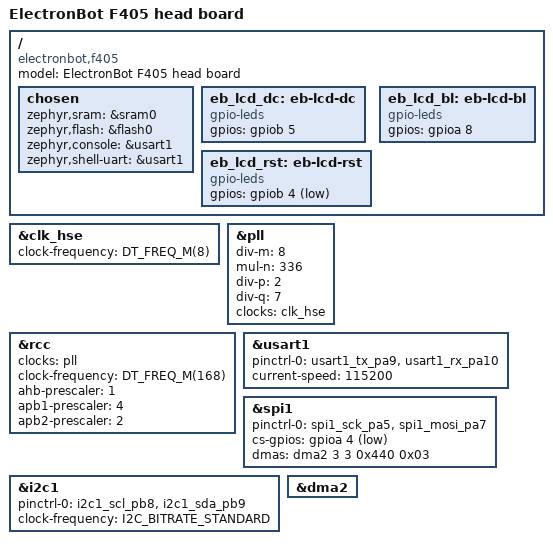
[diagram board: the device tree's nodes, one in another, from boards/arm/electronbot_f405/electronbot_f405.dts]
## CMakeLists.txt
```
# SPDX-License-Identifier: Apache-2.0
cmake_minimum_required(VERSION 3.20.0)

find_package(Zephyr REQUIRED HINTS $ENV{ZEPHYR_BASE})
project(electronbot_zephyr C)

target_sources(app PRIVATE
  src/main.c
  src/robot.c
  src/protocol.c
  src/usb_app.c
  src/display.c
  src/servo_bus.c
)
```

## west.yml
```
# West manifest for the ElectronBot Zephyr head firmware.
#
# Usage (creates a workspace that pulls Zephyr + HAL modules next to this app):
#   west init -l v2/firmware/electronbot-zephyr
#   west update
#   west build -b electronbot_f405 v2/firmware/electronbot-zephyr
#
# Pin to a known-good Zephyr release; bump deliberately.
manifest:
  remotes:
    - name: zephyrproject-rtos
      url-base: https://github.com/zephyrproject-rtos

  projects:
    - name: zephyr
      remote: zephyrproject-rtos
      revision: v3.7.0
      import:
        # Only pull the modules this app needs (HALs/CMSIS) to keep it lean.
        name-allowlist:
          - cmsis
          - hal_stm32

  self:
    path: application
```

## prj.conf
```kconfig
# ElectronBot head firmware (Zephyr) - application config.

# Core
CONFIG_LOG=y
CONFIG_GPIO=y
CONFIG_SPI=y
CONFIG_I2C=y
CONFIG_DMA=y

# FPU (Cortex-M4F)
CONFIG_FPU=y

# USB device stack (legacy stack shown; for usb_device_next swap the symbols).
CONFIG_USB_DEVICE_STACK=y
CONFIG_USB_DEVICE_VID=0x1001
CONFIG_USB_DEVICE_PID=0x8023
CONFIG_USB_DEVICE_MANUFACTURER="Pengzhihui"
CONFIG_USB_DEVICE_PRODUCT="ElectronBot@PZH"

# Reasonable heap/stack for the 43232-byte ping-pong buffers (in BSS, not heap).
CONFIG_MAIN_STACK_SIZE=4096
CONFIG_HEAP_MEM_POOL_SIZE=8192

# Helpful while bringing up.
CONFIG_LOG_DEFAULT_LEVEL=3
CONFIG_ASSERT=y
```

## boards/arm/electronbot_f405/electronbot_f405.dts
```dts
/*
 * ElectronBot head board - STM32F405RGT6.
 *
 * Pin assignments below follow the original design (SPI1 for the GC9A01 LCD,
 * I2C1 SCL=PB8 / SDA=PB9 for the servo bus). CONFIRM against 1.Hardware before
 * relying on them - marked with TODO where the schematic is the source of truth.
 */
/dts-v1/;
#include <st/f4/stm32f405Xg.dtsi>
#include <st/f4/stm32f405rgtx-pinctrl.dtsi>
#include <zephyr/dt-bindings/gpio/gpio.h>

/ {
	model = "ElectronBot F405 head board";
	compatible = "electronbot,f405";

	chosen {
		zephyr,sram = &sram0;
		zephyr,flash = &flash0;
		zephyr,console = &usart1;
		zephyr,shell-uart = &usart1;
	};

	/* LCD control GPIOs (DC / RST / backlight). TODO: confirm pins. */
	eb_lcd_dc: eb-lcd-dc {
		compatible = "gpio-leds";
		gpios = <&gpiob 5 GPIO_ACTIVE_HIGH>;
	};
	eb_lcd_rst: eb-lcd-rst {
		compatible = "gpio-leds";
		gpios = <&gpiob 4 GPIO_ACTIVE_LOW>;
	};
	eb_lcd_bl: eb-lcd-bl {
		compatible = "gpio-leds";
		gpios = <&gpioa 8 GPIO_ACTIVE_HIGH>;
	};
};

/* High-speed external crystal (8 MHz on the original board). */
&clk_hse {
	clock-frequency = <DT_FREQ_M(8)>;
	status = "okay";
};

&pll {
	div-m = <8>;
	mul-n = <336>;
	div-p = <2>;
	div-q = <7>;
	clocks = <&clk_hse>;
	status = "okay";
};

&rcc {
	clocks = <&pll>;
	clock-frequency = <DT_FREQ_M(168)>;
	ahb-prescaler = <1>;
	apb1-prescaler = <4>;
	apb2-prescaler = <2>;
};

&usart1 {
	pinctrl-0 = <&usart1_tx_pa9 &usart1_rx_pa10>;
	pinctrl-names = "default";
	current-speed = <115200>;
	status = "okay";
};

/* GC9A01 LCD bus. */
eb_lcd_spi: &spi1 {
	pinctrl-0 = <&spi1_sck_pa5 &spi1_mosi_pa7>;
	pinctrl-names = "default";
	cs-gpios = <&gpioa 4 GPIO_ACTIVE_LOW>;   /* TODO: confirm CS pin */
	status = "okay";
	/* DMA wiring for stripe streaming. TODO: confirm DMA stream/channel. */
	dmas = <&dma2 3 3 0x440 0x03>;
	dma-names = "tx";
};

/* Servo bus (I2C master). SCL=PB8, SDA=PB9 per the original firmware. */
eb_servo_i2c: &i2c1 {
	pinctrl-0 = <&i2c1_scl_pb8 &i2c1_sda_pb9>;
	pinctrl-names = "default";
	clock-frequency = <I2C_BITRATE_STANDARD>;
	status = "okay";
};

&dma2 {
	status = "okay";
};
```

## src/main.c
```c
/*
 * ElectronBot head firmware - Zephyr port entry point.
 *
 * Target: STM32F405RGT6 (Cortex-M4F). Replaces the original CubeMX/HAL +
 * FreeRTOS super-loop firmware while keeping the host SDK protocol unchanged.
 */
#include <zephyr/kernel.h>
#include <zephyr/logging/log.h>

#include "robot.h"

LOG_MODULE_REGISTER(eb_main, LOG_LEVEL_INF);

int main(void)
{
	LOG_INF("ElectronBot-zephyr boot");

	int rc = eb_robot_init();

	if (rc) {
		LOG_ERR("init failed: %d", rc);
		return rc;
	}

	eb_robot_run(); /* never returns */
	return 0;
}
```

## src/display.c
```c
/*
 * GC9A01 stripe streaming driver (Zephyr SPI + GPIO).
 *
 * Implementation notes:
 *  - Uses the Zephyr SPI driver (async API for DMA-backed transfers where the
 *    SoC SPI supports it). On STM32 the SPI DMA is wired via the devicetree.
 *  - DC/CS/RST/backlight are GPIOs from the devicetree (see board overlay).
 *  - The init sequence below mirrors the original firmware's GC9A01 magic
 *    registers (0xEF / 0xEB / 0xFE ... MADCTL 0x36, COLMOD 0x3A, etc.).
 *
 * Hardware-tuning TODOs are marked; these need a scope/panel to finalize.
 */
#include <zephyr/kernel.h>
#include <zephyr/device.h>
#include <zephyr/drivers/spi.h>
#include <zephyr/drivers/gpio.h>
#include <zephyr/logging/log.h>

#include "display.h"
#include "protocol.h"

LOG_MODULE_REGISTER(eb_display, LOG_LEVEL_INF);

#define SPI_NODE   DT_NODELABEL(eb_lcd_spi)
#define DC_NODE    DT_NODELABEL(eb_lcd_dc)
#define RST_NODE   DT_NODELABEL(eb_lcd_rst)
#define BL_NODE    DT_NODELABEL(eb_lcd_bl)

static const struct device *spi_dev;
static struct gpio_dt_spec dc_gpio  = GPIO_DT_SPEC_GET_OR(DC_NODE,  gpios, {0});
static struct gpio_dt_spec rst_gpio = GPIO_DT_SPEC_GET_OR(RST_NODE, gpios, {0});
static struct gpio_dt_spec bl_gpio  = GPIO_DT_SPEC_GET_OR(BL_NODE,  gpios, {0});

static struct spi_config spi_cfg = {
	.frequency = 40000000U, /* TODO: confirm max stable SPI clock for the panel */
	.operation = SPI_WORD_SET(8) | SPI_TRANSFER_MSB | SPI_OP_MODE_MASTER,
	.slave = 0,
};

/* GC9A01 init program: {cmd, n_args, args...}. Condensed from the original
 * firmware's screen.cpp magic sequence. */
static const uint8_t gc9a01_init[] = {
	0xEF, 0,
	0xEB, 1, 0x14,
	0xFE, 0,
	0xEF, 0,
	0xEB, 1, 0x14,
	0x84, 1, 0x40,
	0x86, 1, 0xFF,
	0x88, 1, 0x0A,
	0x8A, 1, 0x00,
	0x8D, 1, 0x14,
	0x36, 1, 0x48,        /* MADCTL */
	0x3A, 1, 0x06,        /* COLMOD: 18-bit (3 bytes/pixel) */
	0x90, 4, 0x08, 0x08, 0x08, 0x08,
	0xBD, 1, 0x06,
	0xBC, 1, 0x00,
	0xFF, 3, 0x60, 0x01, 0x04,
	0xC3, 1, 0x13,
	0xC4, 1, 0x13,
	0xC9, 1, 0x22,
	0xBE, 1, 0x11,
	0xE1, 2, 0x10, 0x0E,
	0xDF, 3, 0x21, 0x0c, 0x02,
	0x11, 0,              /* sleep out */
	0x00                  /* terminator (cmd 0x00 unused -> end) */
};

static int spi_write_bytes(const uint8_t *data, size_t len)
{
	struct spi_buf buf = { .buf = (void *)data, .len = len };
	struct spi_buf_set set = { .buffers = &buf, .count = 1 };

	return spi_write(spi_dev, &spi_cfg, &set);
}

static void write_cmd(uint8_t cmd)
{
	gpio_pin_set_dt(&dc_gpio, 0); /* command */
	spi_write_bytes(&cmd, 1);
}

static void write_data(const uint8_t *data, size_t len)
{
	gpio_pin_set_dt(&dc_gpio, 1); /* data */
	spi_write_bytes(data, len);
}

static void run_init_program(const uint8_t *prog)
{
	size_t i = 0;

	while (prog[i] != 0x00 || i == 0) {
		uint8_t cmd = prog[i++];
		uint8_t n = prog[i++];

		write_cmd(cmd);
		if (n) {
			write_data(&prog[i], n);
			i += n;
		}
		if (cmd == 0x11) {
			k_msleep(120); /* sleep-out settle */
		}
		if (prog[i] == 0x00) {
			break;
		}
	}
}

int eb_display_init(void)
{
	spi_dev = DEVICE_DT_GET(SPI_NODE);
	if (!device_is_ready(spi_dev)) {
		LOG_ERR("SPI not ready");
		return -ENODEV;
	}
	gpio_pin_configure_dt(&dc_gpio, GPIO_OUTPUT_INACTIVE);
	gpio_pin_configure_dt(&rst_gpio, GPIO_OUTPUT_ACTIVE);
	gpio_pin_configure_dt(&bl_gpio, GPIO_OUTPUT_INACTIVE);

	/* Reset pulse */
	gpio_pin_set_dt(&rst_gpio, 1);
	k_msleep(10);
	gpio_pin_set_dt(&rst_gpio, 0);
	k_msleep(10);
	gpio_pin_set_dt(&rst_gpio, 1);
	k_msleep(120);

	run_init_program(gc9a01_init);

	write_cmd(0x29); /* display on */
	k_msleep(20);
	eb_display_backlight(1);
	LOG_INF("GC9A01 initialized");
	return 0;
}

void eb_display_begin_frame(void)
{
	/* Full-screen address window 0..239 x 0..239. */
	uint8_t col[] = {0x00, 0x00, 0x00, EB_LCD_W - 1};
	uint8_t row[] = {0x00, 0x00, 0x00, EB_LCD_H - 1};

	write_cmd(0x2A); write_data(col, sizeof(col));
	write_cmd(0x2B); write_data(row, sizeof(row));
}

void eb_display_push_stripe(const uint8_t *rgb, size_t len, int first)
{
	write_cmd(first ? 0x2C : 0x3C); /* RAMWR / RAM-continue */
	/* TODO: switch to spi_transceive_signal()/async for true DMA overlap. */
	write_data(rgb, len);
}

void eb_display_wait(void)
{
	/* With synchronous spi_write above this is a no-op. When async DMA is
	 * enabled, block on the SPI completion signal here. */
}

void eb_display_backlight(int on)
{
	gpio_pin_set_dt(&bl_gpio, on ? 1 : 0);
}
```

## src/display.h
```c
/*
 * GC9A01 round 240x240 LCD - stripe streaming over SPI + DMA.
 *
 * The original firmware bypasses a generic display API and streams raw RGB888
 * stripes straight to the panel via SPI DMA, double-buffered so a stripe DMA
 * overlaps the USB receive of the next stripe. We keep that model.
 */
#ifndef ELECTRONBOT_DISPLAY_H_
#define ELECTRONBOT_DISPLAY_H_

#include <stdint.h>
#include <stddef.h>

/* Initialize SPI, control GPIOs (CS/DC/RST/backlight) and run the GC9A01
 * power-on / magic init sequence. Returns 0 on success.
 */
int eb_display_init(void);

/* Begin a new frame (issues column/row address window + RAMWR 0x2C). */
void eb_display_begin_frame(void);

/* Push one RGB888 stripe (EB_STRIPE_BYTES). `first` selects RAMWR (0x2C) vs
 * RAM-continue (0x3C). Transfer is via SPI DMA; returns immediately. Call
 * eb_display_wait() before reusing the same buffer.
 */
void eb_display_push_stripe(const uint8_t *rgb, size_t len, int first);

/* Block until the in-flight DMA stripe completes. */
void eb_display_wait(void);

/* Backlight on/off. */
void eb_display_backlight(int on);

#endif /* ELECTRONBOT_DISPLAY_H_ */
```

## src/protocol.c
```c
/*
 * Extra-data (servo side-channel) encode/decode.
 *
 * Layout (32 bytes):
 *   [0]      enable flag
 *   [1..24]  6 little-endian float32 joint values
 *   [25..31] reserved
 *
 * Uses byte-wise copy so it is endian-safe and alignment-safe regardless of the
 * target (Cortex-M4 is little-endian, but this stays explicit on purpose).
 */
#include <string.h>
#include "protocol.h"

static float load_le_float(const uint8_t *p)
{
	uint32_t v = (uint32_t)p[0] |
		     ((uint32_t)p[1] << 8) |
		     ((uint32_t)p[2] << 16) |
		     ((uint32_t)p[3] << 24);
	float f;

	memcpy(&f, &v, sizeof(f));
	return f;
}

static void store_le_float(uint8_t *p, float f)
{
	uint32_t v;

	memcpy(&v, &f, sizeof(v));
	p[0] = (uint8_t)(v & 0xff);
	p[1] = (uint8_t)((v >> 8) & 0xff);
	p[2] = (uint8_t)((v >> 16) & 0xff);
	p[3] = (uint8_t)((v >> 24) & 0xff);
}

void eb_extra_decode(const uint8_t *buf32, struct eb_extra_data *out)
{
	out->enable = buf32[EB_EXTRA_ENABLE_OFF];
	for (int j = 0; j < EB_JOINT_COUNT; j++) {
		out->joints[j] = load_le_float(buf32 + EB_EXTRA_JOINTS_OFF + j * 4);
	}
}

void eb_extra_encode(const struct eb_extra_data *in, uint8_t *buf32)
{
	memset(buf32, 0, EB_EXTRA_BYTES);
	buf32[EB_EXTRA_ENABLE_OFF] = in->enable;
	for (int j = 0; j < EB_JOINT_COUNT; j++) {
		store_le_float(buf32 + EB_EXTRA_JOINTS_OFF + j * 4, in->joints[j]);
	}
}
```

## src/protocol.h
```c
/*
 * ElectronBot USB wire protocol - byte-compatible with the original host SDK.
 *
 * This is the keystone of the Zephyr port: the host (ElectronBotSDK-LowLevel)
 * is unchanged, so the firmware MUST reproduce this framing exactly.
 *
 * One face frame = 240 x 240 x 3 (RGB888) = 172800 bytes, sent in 4 chunks.
 * Per chunk, the host:
 *   1. reads 32 bytes on EP IN  (the device "request" + telemetry channel),
 *   2. writes 84 x 512 = 43008 bytes of image on EP OUT,
 *   3. writes a 224-byte tail (192 image bytes + 32 extra-data bytes).
 * 4 * (43008 + 192) = 172800 = one full frame.
 *
 * The 224-byte short packet is the end-of-frame delimiter the firmware keys on
 * to swap its receive ping-pong buffer.
 *
 * The 32-byte extra-data block (host -> device, in the tail; device -> host, in
 * the IN request) carries servo data:
 *   byte[0]      = enable flag (1 = drive servos)
 *   byte[1..24]  = 6 IEEE-754 little-endian float joint set-points / measured
 *   byte[25..31] = reserved
 */
#ifndef ELECTRONBOT_PROTOCOL_H_
#define ELECTRONBOT_PROTOCOL_H_

#include <stdint.h>

/* USB identity - must match the host defaults (electron_low_level.h). */
#define EB_USB_VID            0x1001
#define EB_USB_PID            0x8023
#define EB_USB_MANUFACTURER   "Pengzhihui"
#define EB_USB_PRODUCT        "ElectronBot@PZH"

/* Bulk endpoints (host view): OUT 0x01 (host->dev), IN 0x81 (dev->host). */
#define EB_EP_OUT             0x01
#define EB_EP_IN              0x81

/* Display geometry. */
#define EB_LCD_W              240
#define EB_LCD_H              240
#define EB_BYTES_PER_PIXEL    3
#define EB_FRAME_BYTES        (EB_LCD_W * EB_LCD_H * EB_BYTES_PER_PIXEL) /* 172800 */

/* Framing. */
#define EB_CHUNKS             4
#define EB_CHUNK_PACKETS      84
#define EB_PACKET_SIZE        512
#define EB_CHUNK_BODY         (EB_CHUNK_PACKETS * EB_PACKET_SIZE)        /* 43008 */
#define EB_TAIL_SIZE          224
#define EB_TAIL_IMAGE_BYTES   192
#define EB_EXTRA_BYTES        32
#define EB_CHUNK_IMAGE_BYTES  (EB_CHUNK_BODY + EB_TAIL_IMAGE_BYTES)     /* 43200 */

/* One LCD stripe rendered per chunk: 60 rows x 240 x 3 = 43200 bytes. */
#define EB_STRIPE_ROWS        (EB_LCD_H / EB_CHUNKS)                    /* 60 */
#define EB_STRIPE_BYTES       (EB_STRIPE_ROWS * EB_LCD_W * EB_BYTES_PER_PIXEL)

/* Servo channel layout inside the 32-byte extra-data block. */
#define EB_JOINT_COUNT        6
#define EB_EXTRA_ENABLE_OFF   0
#define EB_EXTRA_JOINTS_OFF   1   /* 6 * float32, little-endian */

/* Decoded extra-data block. */
struct eb_extra_data {
	uint8_t enable;
	float   joints[EB_JOINT_COUNT];
};

/* Receive buffer: one full frame plus the trailing 32-byte control block.
 * Matches the host/firmware rxData[2][60*240*3 + 32] ping-pong sizing.
 */
#define EB_RX_BUF_BYTES       (EB_STRIPE_BYTES + EB_EXTRA_BYTES) /* 43232 */

/* Pack/unpack helpers (implemented in protocol.c). */
void eb_extra_decode(const uint8_t *buf32, struct eb_extra_data *out);
void eb_extra_encode(const struct eb_extra_data *in, uint8_t *buf32);

#endif /* ELECTRONBOT_PROTOCOL_H_ */
```

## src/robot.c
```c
/*
 * Robot orchestration.
 */
#include <zephyr/kernel.h>
#include <zephyr/logging/log.h>
#include <string.h>

#include "robot.h"
#include "usb_app.h"
#include "display.h"
#include "servo_bus.h"

LOG_MODULE_REGISTER(eb_robot, LOG_LEVEL_INF);

/* j1=head, j2=L-open, j3=R-lift, j4=R-open, j5=L-lift, j6=body */
const float eb_joint_limit[EB_JOINT_COUNT] = {15.f, 30.f, 180.f, 30.f, 180.f, 90.f};
const int   eb_joint_invert[EB_JOINT_COUNT] = {0, 0, 0, 1, 1, 0};

/* Latest measured angles, returned to the host on each IN handshake. */
static float s_measured[EB_JOINT_COUNT];
static struct eb_extra_data s_last_cmd;

float eb_robot_map_angle(int j, float model_angle)
{
	float lim = eb_joint_limit[j];
	float a = model_angle;

	if (a > lim) {
		a = lim;
	}
	if (a < -lim) {
		a = -lim;
	}
	if (eb_joint_invert[j]) {
		a = -a;
	}
	return a;
}

/* Called by the USB transport for each completed stripe (chunk). */
static void on_chunk(int chunk_index, const uint8_t *stripe_rgb,
		     const struct eb_extra_data *extra)
{
	if (chunk_index == 0) {
		eb_display_begin_frame();
	}

	eb_display_wait(); /* ensure previous DMA done before reusing the bus */
	eb_display_push_stripe(stripe_rgb, EB_STRIPE_BYTES, chunk_index == 0);

	/* The extra-data block is identical across the 4 chunks of a frame; act
	 * on the last one to push servo set-points once per frame. */
	if (chunk_index == EB_CHUNKS - 1) {
		s_last_cmd = *extra;
		float mapped[EB_JOINT_COUNT];

		for (int j = 0; j < EB_JOINT_COUNT; j++) {
			mapped[j] = eb_robot_map_angle(j, extra->joints[j]);
		}
		eb_servo_update_all(mapped, extra->enable);

		/* refresh telemetry (best-effort, non-blocking cadence) */
		for (int j = 0; j < EB_JOINT_COUNT; j++) {
			(void)eb_servo_get_angle(j, &s_measured[j]);
		}
	}
}

/* Called when the host reads the IN endpoint: return measured joints. */
static void fill_telemetry(uint8_t out_buf32[EB_EXTRA_BYTES])
{
	struct eb_extra_data tel;

	tel.enable = s_last_cmd.enable;
	memcpy(tel.joints, s_measured, sizeof(s_measured));
	eb_extra_encode(&tel, out_buf32);
}

int eb_robot_init(void)
{
	int rc;

	rc = eb_display_init();
	if (rc) {
		return rc;
	}
	rc = eb_servo_init();
	if (rc) {
		return rc;
	}

	/* Give the six servo MCUs time to boot before any I2C traffic, exactly
	 * like the original HAL_Delay(2000) guard against bus lockup. */
	k_msleep(2000);
	eb_servo_enable_all(0);

	return eb_usb_init(on_chunk, fill_telemetry);
}

void eb_robot_run(void)
{
	LOG_INF("ElectronBot (Zephyr) running");
	while (1) {
		/* The pipeline is interrupt/endpoint-driven; idle here. */
		k_msleep(100);
	}
}
```

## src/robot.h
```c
/*
 * Robot orchestration - ties the USB transport, display and servo bus together.
 *
 * Mirrors the original head firmware's per-frame flow: render each received
 * stripe to the LCD, and after a full frame push the 6 joint set-points (with
 * per-joint limits) to the servo bus, while returning measured angles back to
 * the host on the IN handshake.
 */
#ifndef ELECTRONBOT_ROBOT_H_
#define ELECTRONBOT_ROBOT_H_

#include "protocol.h"

/* Per-joint mechanical limits (deg), j1..j6. */
extern const float eb_joint_limit[EB_JOINT_COUNT];
extern const int   eb_joint_invert[EB_JOINT_COUNT];

int  eb_robot_init(void);
void eb_robot_run(void); /* never returns */

/* Map a host "model angle" to a raw servo angle (clamp + invert). */
float eb_robot_map_angle(int joint_index, float model_angle);

#endif /* ELECTRONBOT_ROBOT_H_ */
```

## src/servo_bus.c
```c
/*
 * I2C master to the ServoDrive joint boards (Zephyr i2c API).
 *
 * Per joint, a "set angle" is a 5-byte write: [opcode][float32 LE].
 * A "get angle" writes the opcode then reads 4 bytes (float32 LE).
 */
#include <zephyr/kernel.h>
#include <zephyr/device.h>
#include <zephyr/drivers/i2c.h>
#include <zephyr/logging/log.h>
#include <string.h>

#include "servo_bus.h"

LOG_MODULE_REGISTER(eb_servo, LOG_LEVEL_INF);

#define I2C_NODE DT_NODELABEL(eb_servo_i2c)

static const struct device *i2c_dev;

/* j1=head, j2=L-arm-open, j3=R-arm-lift, j4=R-arm-open, j5=L-arm-lift, j6=body */
const uint8_t eb_servo_addr[EB_JOINT_COUNT] = {
	0x02 >> 1, 0x04 >> 1, 0x06 >> 1, 0x08 >> 1, 0x0a >> 1, 0x0c >> 1
};

static void pack_le_float(uint8_t *p, float f)
{
	uint32_t v;

	memcpy(&v, &f, sizeof(v));
	p[0] = v & 0xff; p[1] = (v >> 8) & 0xff;
	p[2] = (v >> 16) & 0xff; p[3] = (v >> 24) & 0xff;
}

static float unpack_le_float(const uint8_t *p)
{
	uint32_t v = (uint32_t)p[0] | ((uint32_t)p[1] << 8) |
		     ((uint32_t)p[2] << 16) | ((uint32_t)p[3] << 24);
	float f;

	memcpy(&f, &v, sizeof(f));
	return f;
}

int eb_servo_init(void)
{
	i2c_dev = DEVICE_DT_GET(I2C_NODE);
	if (!device_is_ready(i2c_dev)) {
		LOG_ERR("I2C not ready");
		return -ENODEV;
	}
	/* Standard mode 100kHz to match the original bus. */
	i2c_configure(i2c_dev, I2C_SPEED_SET(I2C_SPEED_STANDARD) | I2C_MODE_CONTROLLER);
	return 0;
}

int eb_servo_set_angle(int j, float angle_deg)
{
	uint8_t buf[5];

	if (j < 0 || j >= EB_JOINT_COUNT) {
		return -EINVAL;
	}
	buf[0] = EB_SERVO_SET_ANGLE;
	pack_le_float(&buf[1], angle_deg);
	return i2c_write(i2c_dev, buf, sizeof(buf), eb_servo_addr[j]);
}

int eb_servo_get_angle(int j, float *out)
{
	uint8_t op = EB_SERVO_GET_ANGLE;
	uint8_t rx[4];
	int rc;

	if (j < 0 || j >= EB_JOINT_COUNT) {
		return -EINVAL;
	}
	rc = i2c_write(i2c_dev, &op, 1, eb_servo_addr[j]);
	if (rc) {
		return rc;
	}
	rc = i2c_read(i2c_dev, rx, sizeof(rx), eb_servo_addr[j]);
	if (rc) {
		return rc;
	}
	*out = unpack_le_float(rx);
	return 0;
}

void eb_servo_enable_all(int enable)
{
	uint8_t buf[5] = { EB_SERVO_ENABLE, 0, 0, 0, 0 };

	buf[1] = enable ? 1 : 0;
	for (int j = 0; j < EB_JOINT_COUNT; j++) {
		(void)i2c_write(i2c_dev, buf, sizeof(buf), eb_servo_addr[j]);
	}
}

void eb_servo_update_all(const float joints[EB_JOINT_COUNT], int enable)
{
	if (!enable) {
		return;
	}
	for (int j = 0; j < EB_JOINT_COUNT; j++) {
		(void)eb_servo_set_angle(j, joints[j]);
	}
}
```

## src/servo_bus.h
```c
/*
 * Servo bus - I2C master to the six ServoDrive joint boards.
 *
 * The head MCU is the I2C master; each joint is a slave at an even address
 * (2,4,6,8,10,12). A command is a 5-byte write (opcode + float32), with an
 * optional 5-byte read for telemetry.
 */
#ifndef ELECTRONBOT_SERVO_BUS_H_
#define ELECTRONBOT_SERVO_BUS_H_

#include <stdint.h>
#include "protocol.h"

/* I2C opcodes (see docs/recommendations + robot9.png). */
#define EB_SERVO_SET_ANGLE     0x01
#define EB_SERVO_SET_VEL       0x02
#define EB_SERVO_SET_TORQUE    0x03
#define EB_SERVO_GET_ANGLE     0x11
#define EB_SERVO_GET_VEL       0x12
#define EB_SERVO_ENABLE        0xff

/* 7-bit slave addresses per joint index (j1..j6). */
extern const uint8_t eb_servo_addr[EB_JOINT_COUNT];

int  eb_servo_init(void);
int  eb_servo_set_angle(int joint_index, float angle_deg);
int  eb_servo_get_angle(int joint_index, float *angle_deg_out);
void eb_servo_enable_all(int enable);

/* Push all six set-points (used per frame). `enable` mirrors the host flag. */
void eb_servo_update_all(const float joints[EB_JOINT_COUNT], int enable);

#endif /* ELECTRONBOT_SERVO_BUS_H_ */
```

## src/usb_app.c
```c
/*
 * USB bulk transport (Zephyr) implementing the ElectronBot frame handshake.
 *
 * Per chunk (the device side mirrors the host's SyncTask):
 *   1. The device makes 32 bytes of telemetry available on EP IN; the host
 *      reads it (this is the "request"/handshake + measured-joints channel).
 *   2. The host writes 84 x 512 bytes of image to EP OUT -> accumulated.
 *   3. The host writes a 224-byte tail (192 image + 32 extra) -> completes the
 *      stripe and triggers the chunk callback; the 224-byte short packet is the
 *      delimiter that advances/wraps the ping-pong buffer.
 *
 * This file targets Zephyr's USB device stack. The exact descriptor/class glue
 * differs between the legacy `usb_device` stack and `usb_device_next`; the
 * structure here is stack-agnostic and the integration points are marked TODO.
 * The framing/state machine itself is final and matches the host byte-for-byte.
 */
#include <zephyr/kernel.h>
#include <zephyr/logging/log.h>
#include <string.h>

#include "usb_app.h"
#include "protocol.h"

LOG_MODULE_REGISTER(eb_usb, LOG_LEVEL_INF);

static eb_chunk_cb_t          s_on_chunk;
static eb_fill_telemetry_cb_t s_fill_telemetry;
static volatile int           s_ready;

/* Ping-pong stripe buffers: [body 43008][tail-image 192][extra 32]. */
static uint8_t s_rx[2][EB_RX_BUF_BYTES];
static int     s_rx_index;
static size_t  s_rx_off;
static int     s_chunk;

/* Called by the OUT endpoint handler with each received bulk packet.
 * Aggregates by length: 512-byte packets are body data; a 224-byte packet is
 * the chunk terminator. */
static void on_out_packet(const uint8_t *data, size_t len)
{
	uint8_t *buf = s_rx[s_rx_index];

	if (len == EB_PACKET_SIZE) {
		if (s_rx_off + len <= EB_CHUNK_BODY) {
			memcpy(buf + s_rx_off, data, len);
			s_rx_off += len;
		}
		return;
	}

	if (len == EB_TAIL_SIZE) {
		/* 192 image bytes complete the stripe, 32 bytes are extra-data. */
		memcpy(buf + EB_CHUNK_BODY, data, EB_TAIL_IMAGE_BYTES);

		struct eb_extra_data extra;
		eb_extra_decode(data + EB_TAIL_IMAGE_BYTES, &extra);

		if (s_on_chunk) {
			s_on_chunk(s_chunk, buf, &extra);
		}

		/* advance chunk; wrap frame after 4 chunks, flip ping-pong. */
		s_chunk = (s_chunk + 1) % EB_CHUNKS;
		s_rx_off = 0;
		s_rx_index ^= 1;
		return;
	}

	LOG_WARN("unexpected OUT packet len=%u", (unsigned)len);
}

/* Called when the host issues an IN read: hand back 32 telemetry bytes. */
static void on_in_request(uint8_t *out, size_t *out_len)
{
	if (s_fill_telemetry) {
		s_fill_telemetry(out);
	} else {
		memset(out, 0, EB_EXTRA_BYTES);
	}
	*out_len = EB_EXTRA_BYTES;
}

int eb_usb_init(eb_chunk_cb_t on_chunk, eb_fill_telemetry_cb_t fill_telemetry)
{
	s_on_chunk = on_chunk;
	s_fill_telemetry = fill_telemetry;
	s_rx_index = 0;
	s_rx_off = 0;
	s_chunk = 0;

	/*
	 * TODO (stack integration):
	 *  - Register a vendor/bulk class with VID=EB_USB_VID, PID=EB_USB_PID,
	 *    manufacturer/product strings, one OUT (EB_EP_OUT) and one IN
	 *    (EB_EP_IN) endpoint, wMaxPacketSize 512 (HS) / 64 (FS).
	 *  - Wire the OUT endpoint completion to on_out_packet(data, len).
	 *  - Wire the IN endpoint request to on_in_request(buf, &len) and submit.
	 *  - Set s_ready = 1 on the SET_CONFIGURATION event.
	 *  - usb_enable().
	 *
	 * The two functions above (on_out_packet / on_in_request) are the only
	 * coupling points; the protocol logic is complete.
	 */
	(void)on_in_request; /* referenced by the endpoint glue once wired */
	LOG_INF("eb_usb framing ready (endpoint glue is the integration TODO)");
	return 0;
}

int eb_usb_ready(void)
{
	return s_ready;
}
```

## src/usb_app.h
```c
/*
 * USB bulk transport for the ElectronBot frame protocol.
 *
 * The original device enumerates as CDC but is driven as a raw bulk pipe. On
 * Zephyr we expose a minimal vendor/bulk interface with one OUT and one IN
 * endpoint and implement the chunked frame handshake (see protocol.h).
 */
#ifndef ELECTRONBOT_USB_APP_H_
#define ELECTRONBOT_USB_APP_H_

#include <stdint.h>
#include "protocol.h"

/* Callback invoked when a full frame has been received into a stripe buffer.
 * `stripe_rgb` points to EB_STRIPE_BYTES of RGB888; `extra` is the decoded
 * 32-byte side-channel for that chunk.
 */
typedef void (*eb_chunk_cb_t)(int chunk_index,
			      const uint8_t *stripe_rgb,
			      const struct eb_extra_data *extra);

/* Provide the telemetry the device returns on each IN request (measured
 * joints). The transport copies 32 bytes from here when the host reads. */
typedef void (*eb_fill_telemetry_cb_t)(uint8_t out_buf32[EB_EXTRA_BYTES]);

int eb_usb_init(eb_chunk_cb_t on_chunk, eb_fill_telemetry_cb_t fill_telemetry);

/* True once the host has configured the device. */
int eb_usb_ready(void);

#endif /* ELECTRONBOT_USB_APP_H_ */
```
